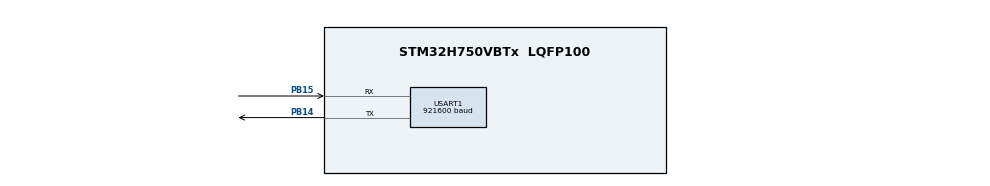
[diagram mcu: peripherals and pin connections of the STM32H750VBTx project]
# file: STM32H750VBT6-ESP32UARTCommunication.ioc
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CORTEX_M7.default_mode_Activation=1
Dma.Request0=USART1_RX
Dma.USART1_RX.0.Direction=DMA_PERIPH_TO_MEMORY
Dma.USART1_RX.0.EventEnable=DISABLE
Dma.USART1_RX.0.FIFOMode=DMA_FIFOMODE_DISABLE
Dma.USART1_RX.0.Instance=DMA1_Stream0
Dma.USART1_RX.0.MemDataAlignment=DMA_MDATAALIGN_BYTE
Dma.USART1_RX.0.MemInc=DMA_MINC_ENABLE
Dma.USART1_RX.0.Mode=DMA_CIRCULAR
Dma.USART1_RX.0.PeriphDataAlignment=DMA_PDATAALIGN_BYTE
Dma.USART1_RX.0.PeriphInc=DMA_PINC_DISABLE
Dma.USART1_RX.0.Polarity=HAL_DMAMUX_REQ_GEN_RISING
Dma.USART1_RX.0.Priority=DMA_PRIORITY_LOW
Dma.USART1_RX.0.RequestNumber=1
Dma.USART1_RX.0.SignalID=NONE
Dma.USART1_RX.0.SyncEnable=DISABLE
Dma.USART1_RX.0.SyncPolarity=HAL_DMAMUX_SYNC_NO_EVENT
Dma.USART1_RX.0.SyncRequestNumber=1
Dma.USART1_RX.0.SyncSignalID=NONE
Mcu.Family=STM32H7
Mcu.Name=STM32H750VBTx
Mcu.Package=LQFP100
NVIC.DMA1_Stream0_IRQn=true\:0\:0\:false\:false\:true\:false\:true\:true
NVIC.PriorityGroup=NVIC_PRIORITYGROUP_4
NVIC.TIM2_IRQn=true\:15\:0\:false\:false\:true\:false\:true\:true
NVIC.TimeBase=TIM2_IRQn
NVIC.TimeBaseIP=TIM2
PA13\ (JTMS/SWDIO).Signal=DEBUG_JTMS-SWDIO
PA14\ (JTCK/SWCLK).Signal=DEBUG_JTCK-SWCLK
PB14.Mode=Asynchronous
PB14.Signal=USART1_TX
PB15.Mode=Asynchronous
PB15.Signal=USART1_RX
PH0-OSC_IN\ (PH0).Mode=HSE-External-Oscillator
PH0-OSC_IN\ (PH0).Signal=RCC_OSC_IN
PH1-OSC_OUT\ (PH1).Mode=HSE-External-Oscillator
PH1-OSC_OUT\ (PH1).Signal=RCC_OSC_OUT
ProjectManager.HeapSize=0x200
ProjectManager.StackSize=0x400
ProjectManager.TargetToolchain=CMake
RCC.ADCFreq_Value=50390625
RCC.APB1Freq_Value=120000000
RCC.APB2Freq_Value=120000000
RCC.APB3Freq_Value=120000000
RCC.APB4Freq_Value=120000000
RCC.CortexFreq_Value=480000000
RCC.D1PPRE=RCC_APB3_DIV2
RCC.D2PPRE1=RCC_APB1_DIV2
RCC.D2PPRE2=RCC_APB2_DIV2
RCC.D3PPRE=RCC_APB4_DIV2
RCC.DIVM1=5
RCC.DIVN1=192
RCC.EnbaleCSS=true
RCC.HCLKFreq_Value=240000000
RCC.HPRE=RCC_HCLK_DIV2
RCC.PLLFRACN=0
RCC.PLLSourceVirtual=RCC_PLLSOURCE_HSE
RCC.SYSCLKFreq_VALUE=480000000
RCC.SYSCLKSource=RCC_SYSCLKSOURCE_PLLCLK
RCC.USBFreq_Value=480000000
USART1.BaudRate=921600
USART1.VirtualMode-Asynchronous=VM_ASYNC
VP_MEMORYMAP_VS_MEMORYMAP.Mode=CurAppReg
VP_SYS_VS_tim2.Mode=TIM2
board=custom

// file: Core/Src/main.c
/* USER CODE BEGIN Header */
/**
  ******************************************************************************
  * @file           : main.c
  * @brief          : Main program body
  ******************************************************************************
  * @attention
  *
  * Copyright (c) 2026 STMicroelectronics.
  * All rights reserved.
  *
  * This software is licensed under terms that can be found in the LICENSE file
  * in the root directory of this software component.
  * If no LICENSE file comes with this software, it is provided AS-IS.
  *
  ******************************************************************************
  */
/* USER CODE END Header */
#include "main.h"

/* USER CODE BEGIN Includes */
#include <string.h>     // Required for memcpy to parse binary data
/* USER CODE END Includes */

UART_HandleTypeDef huart1;
DMA_HandleTypeDef hdma_usart1_rx;

/* USER CODE BEGIN PV */
// Raw byte buffer for the 24-bit DMA payload (6 floats * 4 bytes)
uint8_t uart_rx_buffer[24];

// GLOBAL VARIABLES FOR IDE LIVE WATCH
// Watch these variables in your IDE Expressions window to see live updates
volatile float esp_states[6];
volatile uint32_t packet_counter = 0; // Increments every time a valid packet arrives
/* USER CODE END PV */

void SystemClock_Config(void);
static void MPU_Config(void);

/* USER CODE BEGIN 0 */

// UART DMA Receive Complete Callback
void HAL_UART_RxCpltCallback(UART_HandleTypeDef *huart)
{
  if (huart->Instance == USART1)
  {
    // 1. Copy the 24 bytes from the raw buffer into our visible float array
    memcpy((void*)esp_states, uart_rx_buffer, 24);

    // 2. Increment counter so you can visually verify data is streaming in the IDE
    packet_counter++;

    // 3. Re-enable DMA to listen for the next 24-byte transaction
    HAL_UART_Receive_DMA(&huart1, uart_rx_buffer, 24);
  }
}

/* USER CODE END 0 */

int main(void)
{

  /* MPU Configuration--------------------------------------------------------*/
  MPU_Config();

  /* MCU Configuration--------------------------------------------------------*/

  /* Reset of all peripherals, Initializes the Flash interface and the Systick. */
  HAL_Init();

  /* Configure the system clock */
  SystemClock_Config();

  /* Initialize all configured peripherals */
  MX_GPIO_Init();
  MX_DMA_Init();
  MX_USART1_UART_Init();
  /* USER CODE BEGIN 2 */

  // Kick off the non-blocking DMA receiver to start capturing ESP32 data
  HAL_UART_Receive_DMA(&huart1, uart_rx_buffer, 24);

  /* USER CODE END 2 */

  /* Infinite loop */
  while (1)
  {

    /* USER CODE BEGIN 3 */
    // The background DMA + Callback handles data extraction entirely.
    // The CPU can perform other tasks here or sleep.
  }
  /* USER CODE END 3 */
}

void SystemClock_Config(void)
{
  RCC_OscInitTypeDef RCC_OscInitStruct = {0};
  RCC_ClkInitTypeDef RCC_ClkInitStruct = {0};

  /** Supply configuration update enable
  */
  HAL_PWREx_ConfigSupply(PWR_LDO_SUPPLY);

  /** Configure the main internal regulator output voltage
  */
  __HAL_PWR_VOLTAGESCALING_CONFIG(PWR_REGULATOR_VOLTAGE_SCALE1);

  while(!__HAL_PWR_GET_FLAG(PWR_FLAG_VOSRDY)) {}

  __HAL_RCC_SYSCFG_CLK_ENABLE();
  __HAL_PWR_VOLTAGESCALING_CONFIG(PWR_REGULATOR_VOLTAGE_SCALE0);

  while(!__HAL_PWR_GET_FLAG(PWR_FLAG_VOSRDY)) {}

  /** Initializes the RCC Oscillators according to the specified parameters
  * in the RCC_OscInitTypeDef structure.
  */
  RCC_OscInitStruct.OscillatorType = RCC_OSCILLATORTYPE_HSE;
  RCC_OscInitStruct.HSEState = RCC_HSE_ON;
  RCC_OscInitStruct.PLL.PLLState = RCC_PLL_ON;
  RCC_OscInitStruct.PLL.PLLSource = RCC_PLLSOURCE_HSE;
  RCC_OscInitStruct.PLL.PLLM = 5;
  RCC_OscInitStruct.PLL.PLLN = 192;
  RCC_OscInitStruct.PLL.PLLP = 2;
  RCC_OscInitStruct.PLL.PLLQ = 2;
  RCC_OscInitStruct.PLL.PLLR = 2;
  RCC_OscInitStruct.PLL.PLLRGE = RCC_PLL1VCIRANGE_2;
  RCC_OscInitStruct.PLL.PLLVCOSEL = RCC_PLL1VCOWIDE;
  RCC_OscInitStruct.PLL.PLLFRACN = 0;
  if (HAL_RCC_OscConfig(&RCC_OscInitStruct) != HAL_OK)
  {
    Error_Handler();
  }

  /** Initializes the CPU, AHB and APB buses clocks
  */
  RCC_ClkInitStruct.ClockType = RCC_CLOCKTYPE_HCLK|RCC_CLOCKTYPE_SYSCLK
                              |RCC_CLOCKTYPE_PCLK1|RCC_CLOCKTYPE_PCLK2
                              |RCC_CLOCKTYPE_D3PCLK1|RCC_CLOCKTYPE_D1PCLK1;
  RCC_ClkInitStruct.SYSCLKSource = RCC_SYSCLKSOURCE_PLLCLK;
  RCC_ClkInitStruct.SYSCLKDivider = RCC_SYSCLK_DIV1;
  RCC_ClkInitStruct.AHBCLKDivider = RCC_HCLK_DIV2;
  RCC_ClkInitStruct.APB3CLKDivider = RCC_APB3_DIV2;
  RCC_ClkInitStruct.APB1CLKDivider = RCC_APB1_DIV2;
  RCC_ClkInitStruct.APB2CLKDivider = RCC_APB2_DIV2;
  RCC_ClkInitStruct.APB4CLKDivider = RCC_APB4_DIV2;

  if (HAL_RCC_ClockConfig(&RCC_ClkInitStruct, FLASH_LATENCY_4) != HAL_OK)
  {
    Error_Handler();
  }

  /** Enables the Clock Security System
  */
  HAL_RCC_EnableCSS();
}

void MX_USART1_UART_Init(void)
{

  huart1.Instance = USART1;
  huart1.Init.BaudRate = 921600;
  huart1.Init.WordLength = UART_WORDLENGTH_8B;
  huart1.Init.StopBits = UART_STOPBITS_1;
  huart1.Init.Parity = UART_PARITY_NONE;
  huart1.Init.Mode = UART_MODE_TX_RX;
  huart1.Init.HwFlowCtl = UART_HWCONTROL_NONE;
  huart1.Init.OverSampling = UART_OVERSAMPLING_16;
  huart1.Init.OneBitSampling = UART_ONE_BIT_SAMPLE_DISABLE;
  huart1.Init.ClockPrescaler = UART_PRESCALER_DIV1;
  huart1.AdvancedInit.AdvFeatureInit = UART_ADVFEATURE_NO_INIT;
  if (HAL_UART_Init(&huart1) != HAL_OK)
  {
    Error_Handler();
  }
  if (HAL_UARTEx_SetTxFifoThreshold(&huart1, UART_TXFIFO_THRESHOLD_1_8) != HAL_OK)
  {
    Error_Handler();
  }
  if (HAL_UARTEx_SetRxFifoThreshold(&huart1, UART_RXFIFO_THRESHOLD_1_8) != HAL_OK)
  {
    Error_Handler();
  }
  if (HAL_UARTEx_DisableFifoMode(&huart1) != HAL_OK)
  {
    Error_Handler();
  }

}

void MX_DMA_Init(void)
{

  /* DMA controller clock enable */
  __HAL_RCC_DMA1_CLK_ENABLE();

  /* DMA interrupt init */
  /* DMA1_Stream0_IRQn interrupt configuration */
  HAL_NVIC_SetPriority(DMA1_Stream0_IRQn, 0, 0);
  HAL_NVIC_EnableIRQ(DMA1_Stream0_IRQn);

}

void MX_GPIO_Init(void)
{

  /* GPIO Ports Clock Enable */
  __HAL_RCC_GPIOH_CLK_ENABLE();
  __HAL_RCC_GPIOB_CLK_ENABLE();
  __HAL_RCC_GPIOA_CLK_ENABLE();

}

 /* MPU Configuration */

void MPU_Config(void)
{
  MPU_Region_InitTypeDef MPU_InitStruct = {0};

  /* Disables the MPU */
  HAL_MPU_Disable();

  /** Initializes and configures the Region and the memory to be protected
  */
  MPU_InitStruct.Enable = MPU_REGION_ENABLE;
  MPU_InitStruct.Number = MPU_REGION_NUMBER0;
  MPU_InitStruct.BaseAddress = 0x0;
  MPU_InitStruct.Size = MPU_REGION_SIZE_4GB;
  MPU_InitStruct.SubRegionDisable = 0x87;
  MPU_InitStruct.TypeExtField = MPU_TEX_LEVEL0;
  MPU_InitStruct.AccessPermission = MPU_REGION_NO_ACCESS;
  MPU_InitStruct.DisableExec = MPU_INSTRUCTION_ACCESS_DISABLE;
  MPU_InitStruct.IsShareable = MPU_ACCESS_SHAREABLE;
  MPU_InitStruct.IsCacheable = MPU_ACCESS_NOT_CACHEABLE;
  MPU_InitStruct.IsBufferable = MPU_ACCESS_NOT_BUFFERABLE;

  HAL_MPU_ConfigRegion(&MPU_InitStruct);
  /* Enables the MPU */
  HAL_MPU_Enable(MPU_PRIVILEGED_DEFAULT);

}

void HAL_TIM_PeriodElapsedCallback(TIM_HandleTypeDef *htim)
{
  if (htim->Instance == TIM2) {
    HAL_IncTick();
  }
}

void Error_Handler(void)
{
  __disable_irq();
  while (1)
  {
  }
}
